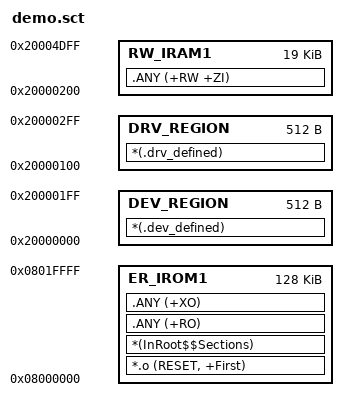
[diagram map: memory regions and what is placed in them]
; *************************************************************
; *** Scatter-Loading Description File generated by uVision ***
; *************************************************************

LR_IROM1 0x08000000 0x00020000  {    ; load region size_region
  ER_IROM1 0x08000000 0x00020000  {  ; load address = execution address
   *.o (RESET, +First)
   *(InRoot$$Sections)
   .ANY (+RO)
   .ANY (+XO)
  }

  DEV_REGION 0x20000000 0x00000200  {  ; RW data
   *(.dev_defined)
  }
  DRV_REGION 0x20000100 0x00000200  {  ; RW data
   *(.drv_defined)
  }
  RW_IRAM1 0x20000200 0x00004C00  {  ; RW data
   .ANY (+RW +ZI)
  }
}
